AUTOSAR XML (schema 4-2-2)
package /STELLANTIS/EPT/ASWCs
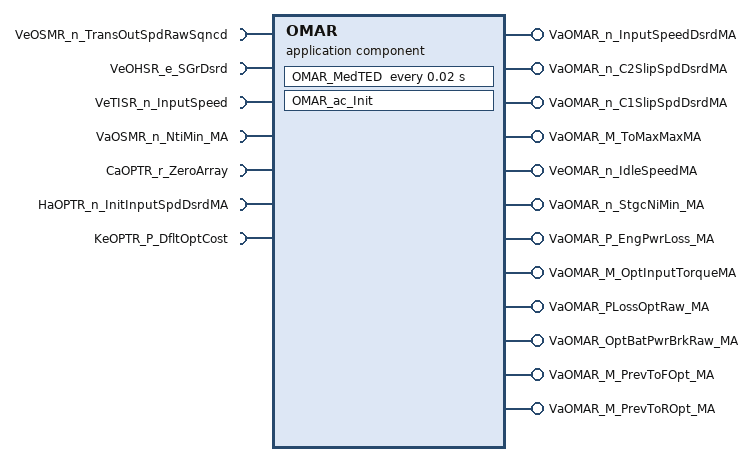
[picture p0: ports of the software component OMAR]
  application sw component type OMAR
    4 x require port:
      VeOSMR_n_TransOutSpdRawSqncd: nonqueued-receiver-com-spec{data-element=Value, init-value=0}, required-interface=VeOSMR_n_TransOutSpdRawSqncd
      VeOHSR_e_SGrDsrd: nonqueued-receiver-com-spec{data-element=Value, init-value=CeOHSR_e_SG_Reverse}, required-interface=VeOHSR_e_SGrDsrd
      VeTISR_n_InputSpeed: nonqueued-receiver-com-spec{data-element=Value, init-value=0}, required-interface=VeTISR_n_InputSpeed
      VaOSMR_n_NtiMin_MA: nonqueued-receiver-com-spec{data-element=Value, init-value=9 x 0}, required-interface=VaOSMR_n_NtiMin_MA
    12 x provide port:
      VaOMAR_n_InputSpeedDsrdMA: nonqueued-sender-com-spec{data-element=Value, init-value=9 x 0}, provided-interface=VaOMAR_n_InputSpeedDsrdMA
      VaOMAR_n_C2SlipSpdDsrdMA: nonqueued-sender-com-spec{data-element=Value, init-value=9 x 0}, provided-interface=VaOMAR_n_C2SlipSpdDsrdMA
      VaOMAR_n_C1SlipSpdDsrdMA: nonqueued-sender-com-spec{data-element=Value, init-value=9 x 0}, provided-interface=VaOMAR_n_C1SlipSpdDsrdMA
      VaOMAR_M_ToMaxMaxMA: nonqueued-sender-com-spec{data-element=Value, init-value=9 x 0}, provided-interface=VaOMAR_M_ToMaxMaxMA
      VeOMAR_n_IdleSpeedMA: nonqueued-sender-com-spec{data-element=Value, init-value=0}, provided-interface=VeOMAR_n_IdleSpeedMA
      VaOMAR_n_StgcNiMin_MA: nonqueued-sender-com-spec{data-element=Value, init-value=9 x 0}, provided-interface=VaOMAR_n_StgcNiMin_MA
      VaOMAR_P_EngPwrLoss_MA: nonqueued-sender-com-spec{data-element=Value, init-value=9 x 0}, provided-interface=VaOMAR_P_EngPwrLoss_MA
      VaOMAR_M_OptInputTorqueMA: nonqueued-sender-com-spec{data-element=Value, init-value=9 x 0}, provided-interface=VaOMAR_M_OptInputTorqueMA
      VaOMAR_PLossOptRaw_MA: nonqueued-sender-com-spec{data-element=Value, init-value=9 x 0}, provided-interface=VaOMAR_PLossOptRaw_MA
      VaOMAR_OptBatPwrBrkRaw_MA: nonqueued-sender-com-spec{data-element=Value, init-value=9 x 0}, provided-interface=VaOMAR_OptBatPwrBrkRaw_MA
      VaOMAR_M_PrevToFOpt_MA: nonqueued-sender-com-spec{data-element=Value, init-value=9 x 0}, provided-interface=VaOMAR_M_PrevToFOpt_MA
      VaOMAR_M_PrevToROpt_MA: nonqueued-sender-com-spec{data-element=Value, init-value=9 x 0}, provided-interface=VaOMAR_M_PrevToROpt_MA
    require port CaOPTR_r_ZeroArray: parameter-require-com-spec{init-value=CaOPTR_r_ZeroArray_CaOPTR_r_ZeroArray:[CaOPTR_r_ZeroArray_CaOPTR_r_ZeroArray_rt_Array_Float_9_1:0, CaOPTR_r_ZeroArray_CaOPTR_r_ZeroArray_rt_Array_Float_9_2:0, CaOPTR_r_ZeroArray_CaOPTR_r_ZeroArray_rt_Array_Float_9_3:0, CaOPTR_r_ZeroArray_CaOPTR_r_ZeroArray_rt_Array_Float_9_4:0, CaOPTR_r_ZeroArray_CaOPTR_r_ZeroArray_rt_Array_Float_9_5:0, CaOPTR_r_ZeroArray_CaOPTR_r_ZeroArray_rt_Array_Float_9_6:0, CaOPTR_r_ZeroArray_CaOPTR_r_ZeroArray_rt_Array_Float_9_7:0, CaOPTR_r_ZeroArray_CaOPTR_r_ZeroArray_rt_Array_Float_9_8:0, CaOPTR_r_ZeroArray_CaOPTR_r_ZeroArray_rt_Array_Float_9_9:0], parameter=CaOPTR_r_ZeroArray}, required-interface=CaOPTR_r_ZeroArray
    require port HaOPTR_n_InitInputSpdDsrdMA: parameter-require-com-spec{init-value=9 x 500, parameter=HaOPTR_n_InitInputSpdDsrdMA}, required-interface=HaOPTR_n_InitInputSpdDsrdMA
    require port KeOPTR_P_DfltOptCost: parameter-require-com-spec{init-value=KeOPTR_P_DfltOptCost_KeOPTR_P_DfltOptCost:1000000, parameter=KeOPTR_P_DfltOptCost}, required-interface=KeOPTR_P_DfltOptCost
    behavior IB_OMAR: data-type-mapping=msADTtoIDTMapping, handle-termination-and-restart=NO-SUPPORT, included-data-type-set=data-type=TeTSXR_e_PrfrdComb
      timing event Event_MedTED: start-on-event=OMAR_MedTED, period=0.02
      init event Event_OMAR_ac_Init: start-on-event=OMAR_ac_Init
      runnable OMAR_ac_Init
        data-send-points:
          12 x access:
            OUT_VaOMAR_n_StgcNiMin_MA_Value: accessed-variable=VaOMAR_n_StgcNiMin_MA.Value
            OUT_VaOMAR_n_C1SlipSpdDsrdMA_Value: accessed-variable=VaOMAR_n_C1SlipSpdDsrdMA.Value
            OUT_VaOMAR_n_C2SlipSpdDsrdMA_Value: accessed-variable=VaOMAR_n_C2SlipSpdDsrdMA.Value
            OUT_VaOMAR_n_InputSpeedDsrdMA_Value: accessed-variable=VaOMAR_n_InputSpeedDsrdMA.Value
            OUT_VeOMAR_n_IdleSpeedMA_Value: accessed-variable=VeOMAR_n_IdleSpeedMA.Value
            OUT_VaOMAR_PLossOptRaw_MA_Value: accessed-variable=VaOMAR_PLossOptRaw_MA.Value
            OUT_VaOMAR_P_EngPwrLoss_MA_Value: accessed-variable=VaOMAR_P_EngPwrLoss_MA.Value
            OUT_VaOMAR_M_ToMaxMaxMA_Value: accessed-variable=VaOMAR_M_ToMaxMaxMA.Value
            OUT_VaOMAR_M_OptInputTorqueMA_Value: accessed-variable=VaOMAR_M_OptInputTorqueMA.Value
            OUT_VaOMAR_OptBatPwrBrkRaw_MA_Value: accessed-variable=VaOMAR_OptBatPwrBrkRaw_MA.Value
            OUT_VaOMAR_M_PrevToFOpt_MA_Value: accessed-variable=VaOMAR_M_PrevToFOpt_MA.Value
            OUT_VaOMAR_M_PrevToROpt_MA_Value: accessed-variable=VaOMAR_M_PrevToROpt_MA.Value
        parameter access CALPRM_CaOPTR_r_ZeroArray_CaOPTR_r_ZeroArray: accessed-parameter=CaOPTR_r_ZeroArray.CaOPTR_r_ZeroArray
        parameter access CALPRM_HaOPTR_n_InitInputSpdDsrdMA_HaOPTR_n_InitInputSpdDsrdMA: accessed-parameter=HaOPTR_n_InitInputSpdDsrdMA.HaOPTR_n_InitInputSpdDsrdMA
        parameter access CALPRM_KeOPTR_P_DfltOptCost_KeOPTR_P_DfltOptCost: accessed-parameter=KeOPTR_P_DfltOptCost.KeOPTR_P_DfltOptCost
      runnable OMAR_MedTED
        data-receive-point-by-arguments:
          access IN_VaOSMR_n_NtiMin_MA_Value: accessed-variable=VaOSMR_n_NtiMin_MA.Value
          access IN_VeTISR_n_InputSpeed_Value: accessed-variable=VeTISR_n_InputSpeed.Value
        data-send-points:
          12 x access:
            OUT_VaOMAR_n_InputSpeedDsrdMA_Value: accessed-variable=VaOMAR_n_InputSpeedDsrdMA.Value
            OUT_VaOMAR_n_C1SlipSpdDsrdMA_Value: accessed-variable=VaOMAR_n_C1SlipSpdDsrdMA.Value
            OUT_VaOMAR_n_C2SlipSpdDsrdMA_Value: accessed-variable=VaOMAR_n_C2SlipSpdDsrdMA.Value
            OUT_VaOMAR_M_ToMaxMaxMA_Value: accessed-variable=VaOMAR_M_ToMaxMaxMA.Value
            OUT_VeOMAR_n_IdleSpeedMA_Value: accessed-variable=VeOMAR_n_IdleSpeedMA.Value
            OUT_VaOMAR_n_StgcNiMin_MA_Value: accessed-variable=VaOMAR_n_StgcNiMin_MA.Value
            OUT_VaOMAR_P_EngPwrLoss_MA_Value: accessed-variable=VaOMAR_P_EngPwrLoss_MA.Value
            OUT_VaOMAR_M_OptInputTorqueMA_Value: accessed-variable=VaOMAR_M_OptInputTorqueMA.Value
            OUT_VaOMAR_PLossOptRaw_MA_Value: accessed-variable=VaOMAR_PLossOptRaw_MA.Value
            OUT_VaOMAR_OptBatPwrBrkRaw_MA_Value: accessed-variable=VaOMAR_OptBatPwrBrkRaw_MA.Value
            OUT_VaOMAR_M_PrevToFOpt_MA_Value: accessed-variable=VaOMAR_M_PrevToFOpt_MA.Value
            OUT_VaOMAR_M_PrevToROpt_MA_Value: accessed-variable=VaOMAR_M_PrevToROpt_MA.Value
        parameter access CALPRM_CaOPTR_r_ZeroArray_CaOPTR_r_ZeroArray: accessed-parameter=CaOPTR_r_ZeroArray.CaOPTR_r_ZeroArray
        parameter access CALPRM_KeOPTR_P_DfltOptCost_KeOPTR_P_DfltOptCost: accessed-parameter=KeOPTR_P_DfltOptCost.KeOPTR_P_DfltOptCost
      17 x variation point proxy, all with category=CONDITION:
        Variant_HSCL_3Mot_Enbl: condition-access=0
        Variant_OMAR_EnblMA: condition-access=0
        Variant_OMAR_EnblMAIdl: condition-access=0
        Variant_OPTR_Enbl3MtrSys: condition-access=0
        Variant_OPTR_EnblPwrPnlCnstr: condition-access=0
        Variant_OPTR_EnblTCCCalc: condition-access=0
        Variant_OPTR_EnblWEDRsrv: condition-access=1
        Variant_OPTR_HiResSrchNiPiLims: condition-access=0
        Variant_OPTR_OptBatPwrBrkEnbl: condition-access=1
        Variant_OPTR_ZrPdlToMinAtTeMin: condition-access=0
        Variant_SCOR_MtrxSelP1P2p5: condition-access=0
        Variant_TSXR_MtrALimToFSel: condition-access=1
        Variant_TSXR_MtrALimToRSel: condition-access=0
        Variant_TSXR_MtrBLimToFSel: condition-access=0
        Variant_TSXR_MtrBLimToRSel: condition-access=1
        Variant_TSXR_MtrCLimToFSel: condition-access=0
        Variant_TSXR_MtrCLimToRSel: condition-access=0
